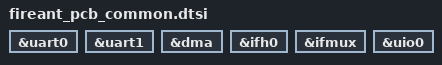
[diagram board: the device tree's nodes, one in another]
// SPDX-License-Identifier: (GPL-2.0+ OR MIT)
/*
 * Copyright (c) 2018 Microsemi Corporation
 */

/dts-v1/;
#include "fireant-soc.dtsi"

&uart0 {
        status = "okay";
};

&uart1 {
        status = "okay";
};

&dma {
	status = "okay";
};

&ifh0 {
	status = "okay";
};

&ifmux {
	status = "okay";
};

&uio0 {
	status = "okay";
};
